VERSION ""

NS_ :

BS_:

BU_: XXX
BO_ 62 ENGINE_DATA: 48 XXX
 SG_ ENGINE_DATA_CHECKSUM_0 : 0|8@1+ (1,0) [0|255] "" XXX
 SG_ ENGINE_DATA_COUNTER_0 : 8|4@1+ (1,0) [0|15] "" XXX
 SG_ NEW_SIGNAL_4 : 17|10@0+ (1,0) [0|255] "" XXX
 SG_ NEW_SIGNAL_5 : 18|1@0+ (1,0) [0|1] "" XXX
 SG_ NEW_SIGNAL_1 : 23|1@0+ (1,0) [0|1] "" XXX
 SG_ ACCEL : 38|15@0- (1,0) [0|255] "" XXX
 SG_ NEW_SIGNAL_8 : 39|1@0+ (1,0) [0|1] "" XXX
 SG_ NEW_SIGNAL_2 : 55|1@0+ (1,0) [0|1] "" XXX
 SG_ ENGINE_DATA_CHECKSUM_1 : 64|8@1+ (1,0) [0|255] "" XXX
 SG_ ENGINE_DATA_COUNTER_1 : 72|4@1+ (1,0) [0|15] "" XXX
 SG_ GAS_POS : 85|14@0+ (1,-600) [0|127] "" XXX
 SG_ SPEED : 103|16@0+ (0.014184,-425.52) [-425.52|504] "kmh" XXX
 SG_ NEW_SIGNAL_6 : 119|16@0+ (1,-32768) [-32768|32767] "" XXX
 SG_ ENGINE_DATA_CHECKSUM_2 : 128|8@1+ (1,0) [0|255] "" XXX
 SG_ ENGINE_DATA_COUNTER_2 : 136|4@1+ (1,0) [0|15] "" XXX
 SG_ NEW_SIGNAL_15 : 151|16@0+ (1,-32768) [-32768|32767] "" XXX
 SG_ NEW_SIGNAL_11 : 166|7@0+ (1,0) [0|127] "" XXX
 SG_ NEW_SIGNAL_12 : 174|7@0+ (1,0) [0|127] "" XXX
 SG_ GAS : 183|8@0+ (1,0) [0|255] "" XXX
 SG_ GAS_PEDAL : 191|8@0+ (1,0) [0|255] "" XXX
 SG_ ENGINE_DATA_CHECKSUM_3 : 192|8@1+ (1,0) [0|255] "" XXX
 SG_ ENGINE_DATA_COUNTER_3 : 200|4@1+ (1,0) [0|15] "" XXX
 SG_ GEAR : 208|3@1+ (1,0) [0|63] "" XXX
 SG_ GEAR_BUTTON : 211|3@1+ (1,0) [0|7] "" XXX
 SG_ CC_STATE : 218|2@0+ (1,0) [0|7] "" XXX
 SG_ BRAKE_PRESS : 220|1@0+ (1,0) [0|1] "" XXX
 SG_ CRUIZE_SPEED : 229|7@0+ (1,0) [0|63] "" XXX
 SG_ SWITCH_TO_P : 234|1@0+ (1,0) [0|1] "" XXX
 SG_ NEW_SIGNAL_3 : 245|1@0+ (1,0) [0|1] "" XXX
 SG_ ENGINE_DATA_CHECKSUM_4 : 256|8@1+ (1,0) [0|255] "" XXX
 SG_ ENGINE_DATA_COUNTER_4 : 264|4@1+ (1,0) [0|15] "" XXX
 SG_ NEW_SIGNAL_14 : 279|16@0+ (1,-32768) [-32768|32767] "" XXX

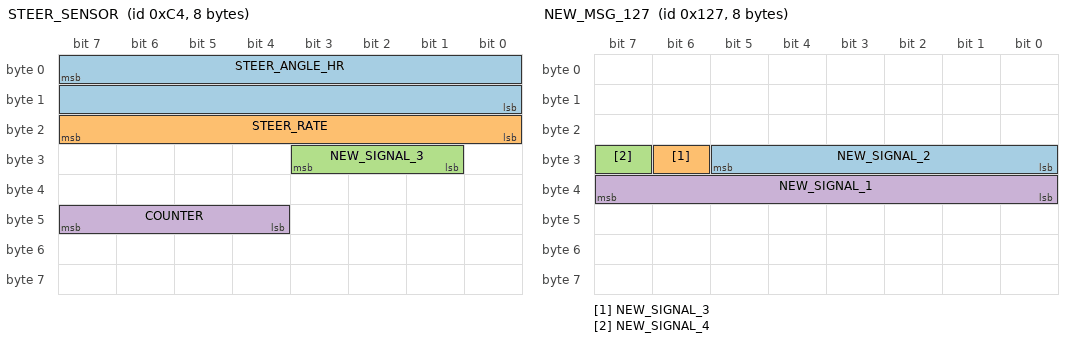
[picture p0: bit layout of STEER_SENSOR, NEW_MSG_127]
BO_ 196 STEER_SENSOR: 8 XXX
 SG_ STEER_ANGLE_HR : 7|16@0+ (0.0625,-2048) [-2048|2047.9375] "deg" XXX
 SG_ STEER_RATE : 16|8@1+ (4,0) [0|1020] "deg/s" XXX
 SG_ NEW_SIGNAL_3 : 25|3@1+ (1,0) [0|3] "" XXX
 SG_ COUNTER : 44|4@1+ (1,0) [0|15] "" XXX

BO_ 295 NEW_MSG_127: 8 XXX
 SG_ NEW_SIGNAL_2 : 24|6@1+ (1,0) [0|63] "" XXX
 SG_ NEW_SIGNAL_3 : 30|1@0+ (1,0) [0|1] "" XXX
 SG_ NEW_SIGNAL_4 : 31|1@0+ (1,0) [0|1] "" XXX
 SG_ NEW_SIGNAL_1 : 39|8@0- (1,0) [0|65535] "" XXX

BO_ 296 NEW_MSG_128: 8 XXX
 SG_ NEW_SIGNAL_1 : 19|12@0+ (1,0) [0|4095] "" XXX

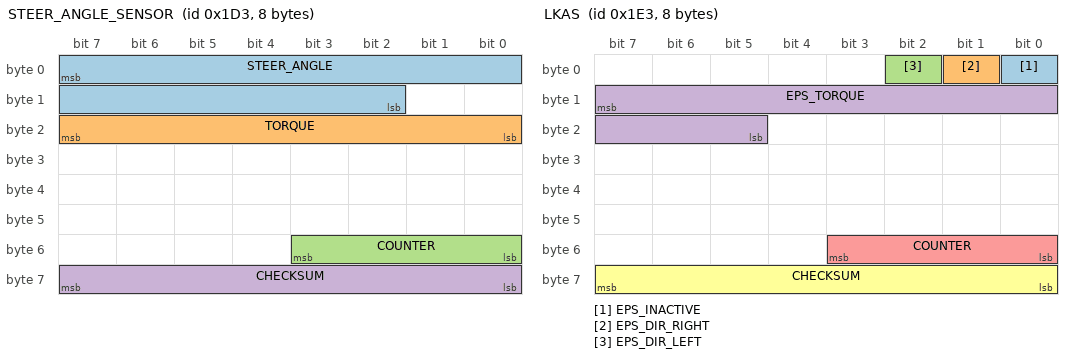
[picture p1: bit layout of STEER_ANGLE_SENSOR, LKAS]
BO_ 467 STEER_ANGLE_SENSOR: 8 XXX
 SG_ STEER_ANGLE : 7|14@0+ (0.1,-780) [-780|858.3] "" XXX
 SG_ TORQUE : 16|8@1- (1,0) [-128|127] "" XXX
 SG_ COUNTER : 48|4@1+ (1,0) [0|15] "" XXX
 SG_ CHECKSUM : 56|8@1+ (1,0) [0|255] "" XXX

BO_ 483 LKAS: 8 XXX
 SG_ EPS_INACTIVE : 0|1@1+ (1,0) [0|1] "" XXX
 SG_ EPS_DIR_RIGHT : 1|1@1+ (1,0) [0|1] "" XXX
 SG_ EPS_DIR_LEFT : 2|1@1+ (1,0) [0|1] "" XXX
 SG_ EPS_TORQUE : 15|11@0+ (1,-1024) [-1024|1023] "" XXX
 SG_ COUNTER : 48|4@1+ (1,0) [0|15] "" XXX
 SG_ CHECKSUM : 63|8@0+ (1,0) [0|255] "" XXX

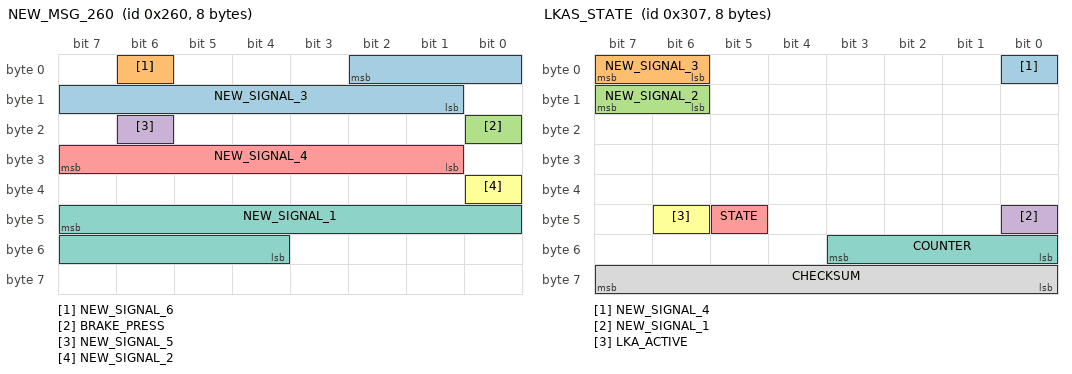
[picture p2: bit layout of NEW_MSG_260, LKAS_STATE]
BO_ 608 NEW_MSG_260: 8 XXX
 SG_ NEW_SIGNAL_3 : 2|10@0+ (1,0) [0|1023] "" XXX
 SG_ NEW_SIGNAL_6 : 6|1@0+ (1,0) [0|1] "" XXX
 SG_ BRAKE_PRESS : 16|1@0+ (1,0) [0|1] "" XXX
 SG_ NEW_SIGNAL_5 : 22|1@0+ (1,0) [0|1] "" XXX
 SG_ NEW_SIGNAL_4 : 31|7@0+ (1,0) [0|127] "" XXX
 SG_ NEW_SIGNAL_2 : 32|1@0+ (1,0) [0|65535] "" XXX
 SG_ NEW_SIGNAL_1 : 47|12@0- (1,0) [0|4095] "" XXX

BO_ 647 NEW_MSG_287: 8 XXX
 SG_ EPB_STATUS : 5|2@1+ (1,0) [0|3] "" XXX
 SG_ SEATBELT_LOCK : 25|1@0+ (1,0) [0|1] "" XXX

BO_ 666 BRAKE_DATA: 8 XXX
 SG_ NEW_SIGNAL_1 : 3|6@0+ (1,0) [0|63] "" XXX
 SG_ BRAKE_POS : 21|12@0- (1,-100) [0|511] "" XXX

BO_ 745 NEW_MSG_2E9: 8 XXX

BO_ 746 DOOR: 8 XXX
 SG_ NEW_SIGNAL_2 : 0|3@1+ (1,0) [0|7] "" XXX
 SG_ NEW_SIGNAL_1 : 11|3@1+ (1,0) [0|7] "" XXX

BO_ 773 NEW_MSG_305: 8 XXX
 SG_ NEW_SIGNAL_2 : 48|4@1+ (1,0) [0|15] "" XXX
 SG_ NEW_SIGNAL_1 : 63|8@0+ (1,0) [0|255] "" XXX

BO_ 775 LKAS_STATE: 8 XXX
 SG_ NEW_SIGNAL_4 : 0|1@0+ (1,0) [0|1] "" XXX
 SG_ NEW_SIGNAL_3 : 6|2@1+ (1,0) [0|3] "" XXX
 SG_ NEW_SIGNAL_2 : 14|2@1+ (1,0) [0|3] "" XXX
 SG_ NEW_SIGNAL_1 : 40|1@0+ (1,0) [0|1] "" XXX
 SG_ STATE : 45|1@0+ (1,0) [0|1] "" XXX
 SG_ LKA_ACTIVE : 46|1@1+ (1,0) [0|3] "" XXX
 SG_ COUNTER : 48|4@1+ (1,0) [0|15] "" XXX
 SG_ CHECKSUM : 63|8@0+ (1,0) [0|255] "" XXX

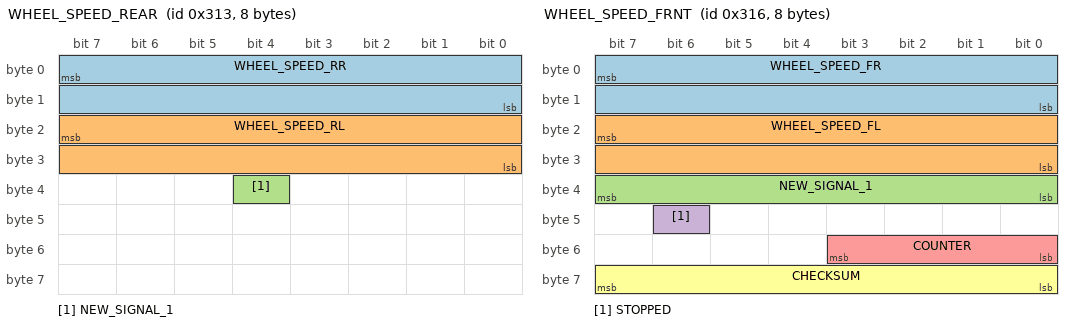
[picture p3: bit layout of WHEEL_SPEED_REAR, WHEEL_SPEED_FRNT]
BO_ 787 WHEEL_SPEED_REAR: 8 XXX
 SG_ WHEEL_SPEED_RR : 7|16@0+ (0.00828,0) [0|32767] "" XXX
 SG_ WHEEL_SPEED_RL : 23|16@0+ (0.00828,0) [0|32767] "" XXX
 SG_ NEW_SIGNAL_1 : 36|1@0+ (1,0) [0|1] "" XXX

BO_ 790 WHEEL_SPEED_FRNT: 8 XXX
 SG_ WHEEL_SPEED_FR : 7|16@0- (0.00829,0) [-2000|32767] "kmh" XXX
 SG_ WHEEL_SPEED_FL : 23|16@0- (0.00829,0) [0|32767] "" XXX
 SG_ NEW_SIGNAL_1 : 32|8@1+ (1,0) [0|31] "" XXX
 SG_ STOPPED : 46|1@0+ (1,0) [0|1] "" XXX
 SG_ COUNTER : 48|4@1+ (1,0) [0|15] "" XXX
 SG_ CHECKSUM : 56|8@1+ (1,0) [0|255] "" XXX

BO_ 793 NEW_MSG_319: 8 XXX

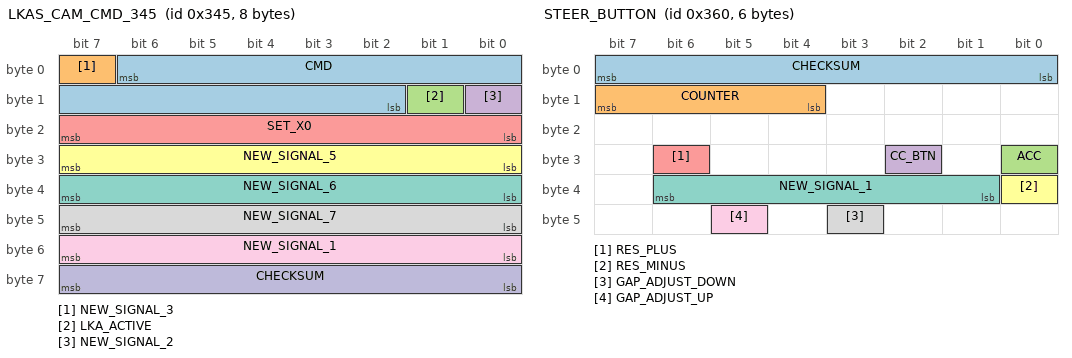
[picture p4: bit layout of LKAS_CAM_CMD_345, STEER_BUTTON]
BO_ 837 LKAS_CAM_CMD_345: 8 XXX
 SG_ CMD : 6|13@0- (1,0) [-4096|4095] "" XXX
 SG_ NEW_SIGNAL_3 : 7|1@0+ (1,0) [0|1] "" XXX
 SG_ LKA_ACTIVE : 9|1@0+ (1,0) [0|1] "" XXX
 SG_ NEW_SIGNAL_2 : 8|1@0+ (1,0) [0|1] "" XXX
 SG_ SET_X0 : 16|8@1+ (1,0) [0|255] "" XXX
 SG_ NEW_SIGNAL_5 : 31|8@0- (1,0) [0|255] "" XXX
 SG_ NEW_SIGNAL_6 : 39|8@0+ (1,0) [0|255] "" XXX
 SG_ NEW_SIGNAL_7 : 47|8@0+ (1,0) [0|255] "" XXX
 SG_ NEW_SIGNAL_1 : 55|8@0+ (1,0) [0|255] "" XXX
 SG_ CHECKSUM : 56|8@1+ (1,0) [0|255] "" XXX

BO_ 864 STEER_BUTTON: 6 XXX
 SG_ CHECKSUM : 0|8@1+ (1,0) [0|255] "" XXX
 SG_ COUNTER : 12|4@1+ (1,0) [0|15] "" XXX
 SG_ ACC : 24|1@0+ (1,0) [0|1] "" XXX
 SG_ CC_BTN : 26|1@0+ (1,0) [0|1] "" XXX
 SG_ RES_PLUS : 30|1@0+ (1,0) [0|1] "" XXX
 SG_ RES_MINUS : 32|1@0+ (1,0) [0|1] "" XXX
 SG_ NEW_SIGNAL_1 : 38|6@0+ (1,0) [0|1] "" XXX
 SG_ GAP_ADJUST_DOWN : 43|1@0+ (1,0) [0|1] "" XXX
 SG_ GAP_ADJUST_UP : 45|1@0+ (1,0) [0|1] "" XXX

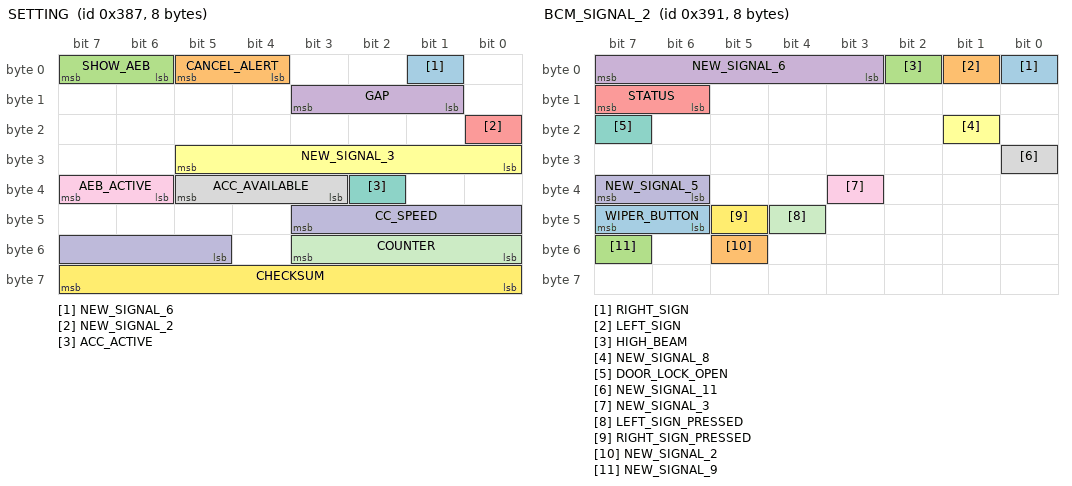
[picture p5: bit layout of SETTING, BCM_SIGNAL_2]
BO_ 903 SETTING: 8 XXX
 SG_ NEW_SIGNAL_6 : 1|1@0+ (1,0) [0|1] "" XXX
 SG_ CANCEL_ALERT : 5|2@0+ (1,0) [0|1] "" XXX
 SG_ SHOW_AEB : 6|2@1+ (1,0) [0|3] "" XXX
 SG_ GAP : 11|3@0+ (1,0) [0|7] "" XXX
 SG_ NEW_SIGNAL_2 : 16|1@0+ (1,0) [0|1] "" XXX
 SG_ NEW_SIGNAL_3 : 29|6@0+ (1,0) [0|31] "" XXX
 SG_ ACC_ACTIVE : 34|1@0+ (1,0) [0|1] "" XXX
 SG_ ACC_AVAILABLE : 35|3@1+ (1,0) [0|15] "" XXX
 SG_ AEB_ACTIVE : 38|2@1+ (1,0) [0|3] "" XXX
 SG_ CC_SPEED : 43|7@0+ (1,0) [0|1023] "" XXX
 SG_ COUNTER : 51|4@0+ (1,0) [0|15] "" XXX
 SG_ CHECKSUM : 63|8@0+ (1,0) [0|255] "" XXX

BO_ 913 BCM_SIGNAL_2: 8 XXX
 SG_ RIGHT_SIGN : 0|1@0+ (1,0) [0|1] "" XXX
 SG_ LEFT_SIGN : 1|1@0+ (1,0) [0|1] "" XXX
 SG_ HIGH_BEAM : 2|1@0+ (1,0) [0|1] "" XXX
 SG_ NEW_SIGNAL_6 : 3|5@1+ (1,0) [0|31] "" XXX
 SG_ STATUS : 15|2@0+ (1,0) [0|63] "" XXX
 SG_ NEW_SIGNAL_8 : 17|1@0+ (1,0) [0|1] "" XXX
 SG_ DOOR_LOCK_OPEN : 23|1@0+ (1,0) [0|1] "" XXX
 SG_ NEW_SIGNAL_11 : 24|1@0+ (1,0) [0|1] "" XXX
 SG_ NEW_SIGNAL_3 : 35|1@0+ (1,0) [0|1] "" XXX
 SG_ NEW_SIGNAL_5 : 38|2@1+ (1,0) [0|3] "" XXX
 SG_ LEFT_SIGN_PRESSED : 44|1@0+ (1,0) [0|1] "" XXX
 SG_ RIGHT_SIGN_PRESSED : 45|1@0+ (1,0) [0|1] "" XXX
 SG_ WIPER_BUTTON : 46|2@1+ (1,0) [0|3] "" XXX
 SG_ NEW_SIGNAL_2 : 53|1@0+ (1,0) [0|1] "" XXX
 SG_ NEW_SIGNAL_9 : 55|1@0+ (1,0) [0|1] "" XXX

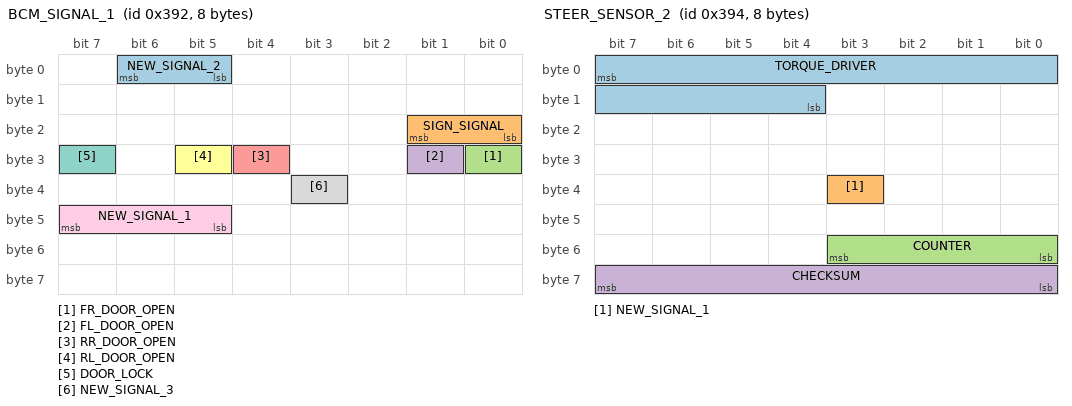
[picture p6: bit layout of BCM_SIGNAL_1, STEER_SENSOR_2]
BO_ 914 BCM_SIGNAL_1: 8 XXX
 SG_ NEW_SIGNAL_2 : 5|2@1+ (1,0) [0|3] "" XXX
 SG_ SIGN_SIGNAL : 16|2@1+ (1,0) [0|3] "" XXX
 SG_ FR_DOOR_OPEN : 24|1@0+ (1,0) [0|1] "" XXX
 SG_ FL_DOOR_OPEN : 25|1@0+ (1,0) [0|1] "" XXX
 SG_ RR_DOOR_OPEN : 28|1@0+ (1,0) [0|1] "" XXX
 SG_ RL_DOOR_OPEN : 29|1@0+ (1,0) [0|1] "" XXX
 SG_ DOOR_LOCK : 31|1@0+ (1,0) [0|1] "" XXX
 SG_ NEW_SIGNAL_3 : 35|1@0+ (1,0) [0|1] "" XXX
 SG_ NEW_SIGNAL_1 : 47|3@0+ (1,0) [0|7] "" XXX

BO_ 916 STEER_SENSOR_2: 8 XXX
 SG_ TORQUE_DRIVER : 7|12@0- (0.24,0) [-491.52|491.28] "" XXX
 SG_ NEW_SIGNAL_1 : 35|1@0+ (1,0) [0|1] "" XXX
 SG_ COUNTER : 48|4@1+ (1,0) [0|15] "" XXX
 SG_ CHECKSUM : 56|8@1+ (1,0) [0|255] "" XXX

BO_ 930 ACC_CMD: 8 XXX
 SG_ CMD : 6|10@0- (1,0) [-511|511] "" XXX
 SG_ ACCEL_ON : 7|1@0+ (1,0) [0|1] "" XXX
 SG_ ACC_STATE : 9|2@0+ (1,0) [0|3] "" XXX
 SG_ STOPPED : 10|1@0+ (1,0) [0|1] "" XXX
 SG_ ACC_STATE_2 : 11|2@1+ (1,0) [0|15] "" XXX
 SG_ NEW_SIGNAL_12 : 16|1@0+ (1,0) [0|1] "" XXX
 SG_ NEW_SIGNAL_9 : 17|1@0+ (1,0) [0|1] "" XXX
 SG_ NEW_SIGNAL_2 : 22|5@0+ (1,0) [0|31] "" XXX
 SG_ STOPPING : 23|1@0+ (1,0) [0|1] "" XXX
 SG_ NEW_SIGNAL_13 : 24|1@0+ (1,0) [0|1] "" XXX
 SG_ NEW_SIGNAL_8 : 25|1@0+ (1,0) [0|1] "" XXX
 SG_ NEW_SIGNAL_5 : 30|5@0+ (1,0) [0|31] "" XXX
 SG_ NEW_SIGNAL_6 : 31|1@0+ (1,0) [0|1] "" XXX
 SG_ NEW_SIGNAL_10 : 32|7@1+ (1,0) [0|255] "" XXX
 SG_ NEW_SIGNAL_3 : 39|1@0+ (1,0) [0|1] "" XXX
 SG_ NEW_SIGNAL_4 : 40|7@1- (1,0) [0|255] "" XXX
 SG_ GAS_PRESSED : 47|1@0+ (1,0) [0|1] "" XXX
 SG_ COUNTER : 48|4@1+ (1,0) [0|15] "" XXX
 SG_ AEB_REQ_STOP : 55|4@0+ (1,0) [0|15] "" XXX
 SG_ CHECKSUM : 56|8@1+ (1,0) [0|255] "" XXX

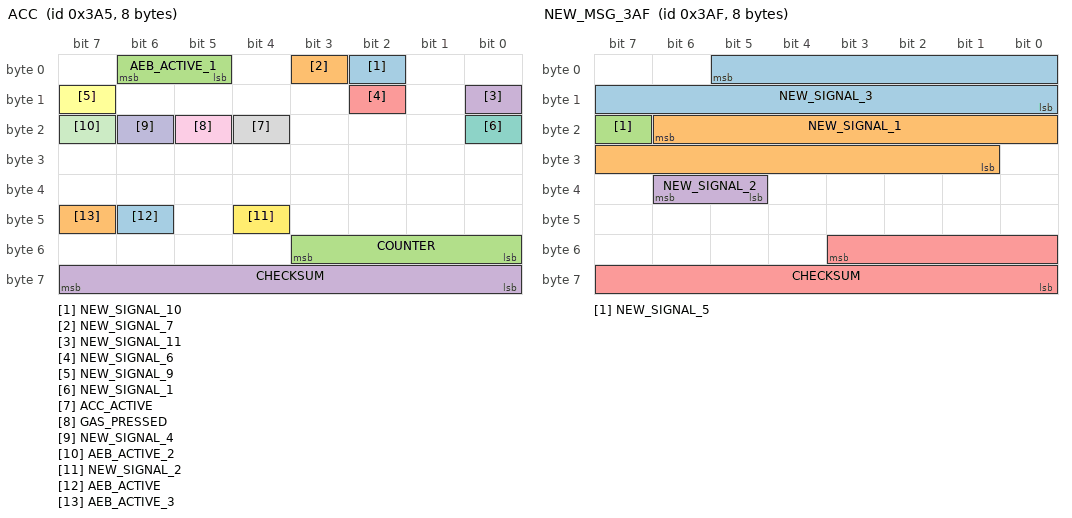
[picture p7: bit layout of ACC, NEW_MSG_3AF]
BO_ 933 ACC: 8 XXX
 SG_ NEW_SIGNAL_10 : 2|1@0+ (1,0) [0|1] "" XXX
 SG_ NEW_SIGNAL_7 : 3|1@0+ (1,0) [0|1] "" XXX
 SG_ AEB_ACTIVE_1 : 5|2@1+ (1,0) [0|3] "" XXX
 SG_ NEW_SIGNAL_11 : 8|1@0+ (1,0) [0|1] "" XXX
 SG_ NEW_SIGNAL_6 : 10|1@0+ (1,0) [0|1] "" XXX
 SG_ NEW_SIGNAL_9 : 15|1@0+ (1,0) [0|1] "" XXX
 SG_ NEW_SIGNAL_1 : 16|1@0+ (1,0) [0|1] "" XXX
 SG_ ACC_ACTIVE : 20|1@0+ (1,0) [0|1] "" XXX
 SG_ GAS_PRESSED : 21|1@0+ (1,0) [0|1] "" XXX
 SG_ NEW_SIGNAL_4 : 22|1@0+ (1,0) [0|1] "" XXX
 SG_ AEB_ACTIVE_2 : 23|1@0+ (1,0) [0|1] "" XXX
 SG_ NEW_SIGNAL_2 : 44|1@0+ (1,0) [0|1] "" XXX
 SG_ AEB_ACTIVE : 46|1@0+ (1,0) [0|1] "" XXX
 SG_ AEB_ACTIVE_3 : 47|1@0+ (1,0) [0|1] "" XXX
 SG_ COUNTER : 48|4@1+ (1,0) [0|15] "" XXX
 SG_ CHECKSUM : 56|8@1+ (1,0) [0|255] "" XXX

BO_ 935 NEW_MSG_3A7: 24 XXX

BO_ 943 NEW_MSG_3AF: 8 XXX
 SG_ NEW_SIGNAL_3 : 5|14@0+ (1,0) [0|16383] "" XXX
 SG_ NEW_SIGNAL_1 : 22|14@0+ (1,0) [0|16383] "" XXX
 SG_ NEW_SIGNAL_5 : 23|1@0+ (1,0) [0|1] "" XXX
 SG_ NEW_SIGNAL_2 : 37|2@1+ (1,0) [0|3] "" XXX
 SG_ CHECKSUM : 51|12@0+ (1,0) [0|4095] "" XXX

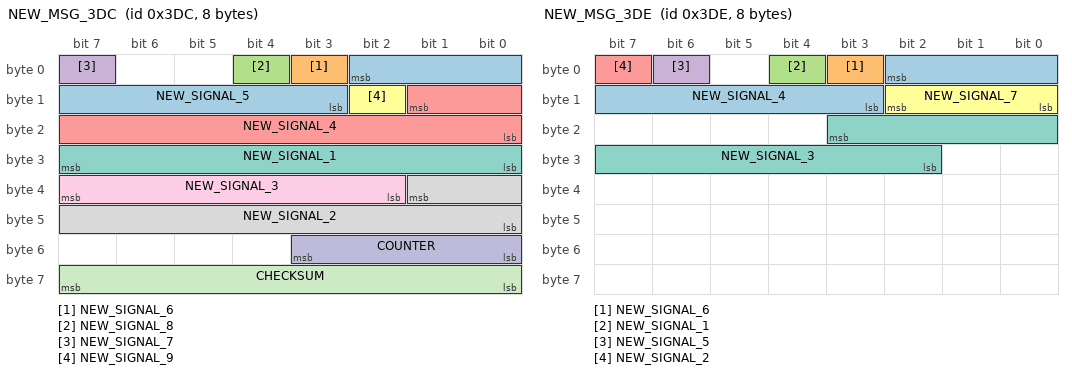
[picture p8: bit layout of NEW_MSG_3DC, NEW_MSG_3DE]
BO_ 988 NEW_MSG_3DC: 8 XXX
 SG_ NEW_SIGNAL_5 : 2|8@0+ (1,0) [0|255] "" XXX
 SG_ NEW_SIGNAL_6 : 3|1@0+ (1,0) [0|1] "" XXX
 SG_ NEW_SIGNAL_8 : 4|1@0+ (1,0) [0|1] "" XXX
 SG_ NEW_SIGNAL_7 : 7|1@1+ (1,0) [0|15] "" XXX
 SG_ NEW_SIGNAL_4 : 9|10@0+ (1,0) [0|8191] "" XXX
 SG_ NEW_SIGNAL_9 : 10|1@0+ (1,0) [0|1] "" XXX
 SG_ NEW_SIGNAL_1 : 31|8@0+ (1,0) [0|8191] "" XXX
 SG_ NEW_SIGNAL_2 : 33|10@0+ (1,0) [0|65535] "" XXX
 SG_ NEW_SIGNAL_3 : 34|6@1+ (1,0) [0|63] "" XXX
 SG_ COUNTER : 48|4@1+ (1,0) [0|15] "" XXX
 SG_ CHECKSUM : 56|8@1+ (1,0) [0|255] "" XXX

BO_ 990 NEW_MSG_3DE: 8 XXX
 SG_ NEW_SIGNAL_4 : 2|8@0+ (1,0) [0|255] "" XXX
 SG_ NEW_SIGNAL_6 : 3|1@0+ (1,0) [0|1] "" XXX
 SG_ NEW_SIGNAL_1 : 4|1@0+ (1,0) [0|1] "" XXX
 SG_ NEW_SIGNAL_5 : 6|1@0+ (1,0) [0|1] "" XXX
 SG_ NEW_SIGNAL_2 : 7|1@0+ (1,0) [0|1] "" XXX
 SG_ NEW_SIGNAL_7 : 10|3@0+ (1,0) [0|7] "" XXX
 SG_ NEW_SIGNAL_3 : 19|10@0+ (1,0) [0|255] "" XXX

BO_ 994 NEW_MSG_3E2: 8 XXX
 SG_ NEW_SIGNAL_2 : 7|1@0+ (1,0) [0|1] "" XXX
 SG_ NEW_SIGNAL_1 : 21|10@0- (1,0) [0|1023] "" XXX

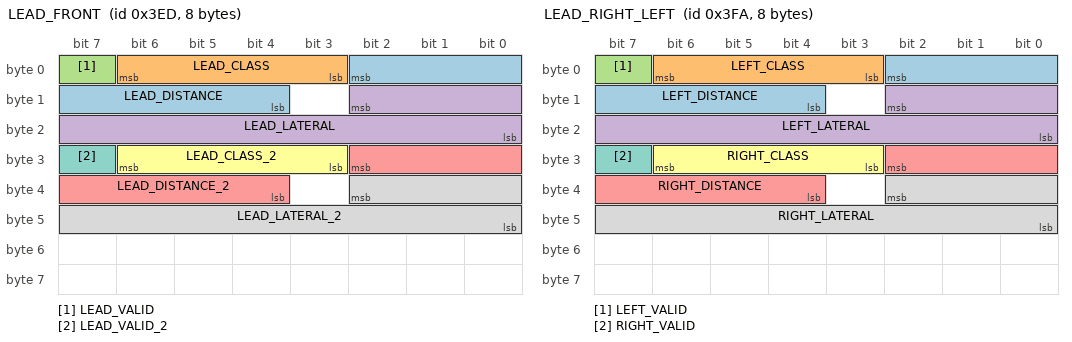
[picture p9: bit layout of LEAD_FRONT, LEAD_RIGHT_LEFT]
BO_ 1005 LEAD_FRONT: 8 XXX
 SG_ LEAD_DISTANCE : 2|7@0+ (1,0) [0|127] "m" XXX
 SG_ LEAD_CLASS : 6|4@0+ (1,0) [0|15] "" XXX
 SG_ LEAD_VALID : 7|1@0+ (1,0) [0|1] "" XXX
 SG_ LEAD_LATERAL : 10|11@0+ (0.04,-40) [-40|41.88] "m" XXX
 SG_ LEAD_DISTANCE_2 : 26|7@0+ (1,0) [0|127] "m" XXX
 SG_ LEAD_CLASS_2 : 30|4@0+ (1,0) [0|15] "" XXX
 SG_ LEAD_VALID_2 : 31|1@0+ (1,0) [0|1] "" XXX
 SG_ LEAD_LATERAL_2 : 34|11@0+ (0.04,-40) [-40|41.88] "m" XXX

BO_ 1008 NEW_MSG_3F0: 8 XXX

BO_ 1018 LEAD_RIGHT_LEFT: 8 XXX
 SG_ LEFT_DISTANCE : 2|7@0+ (1,0) [0|127] "m" XXX
 SG_ LEFT_CLASS : 6|4@0+ (1,0) [0|15] "" XXX
 SG_ LEFT_VALID : 7|1@0+ (1,0) [0|1] "" XXX
 SG_ LEFT_LATERAL : 10|11@0+ (0.04,-40) [-40|41.88] "m" XXX
 SG_ RIGHT_DISTANCE : 26|7@0+ (1,0) [0|127] "m" XXX
 SG_ RIGHT_CLASS : 30|4@0+ (1,0) [0|15] "" XXX
 SG_ RIGHT_VALID : 31|1@0+ (1,0) [0|1] "" XXX
 SG_ RIGHT_LATERAL : 34|11@0+ (0.04,-40) [-40|41.88] "m" XXX

BO_ 1020 HUD_ALERT: 8 XXX
 SG_ NEW_SIGNAL_1 : 0|8@1+ (1,0) [0|255] "" XXX
 SG_ NEW_SIGNAL_2 : 8|8@1+ (1,0) [0|255] "" XXX
 SG_ NEW_SIGNAL_6 : 16|2@1+ (1,0) [0|3] "" XXX
 SG_ NEW_SIGNAL_5 : 18|1@1+ (1,0) [0|1] "" XXX
 SG_ NEW_SIGNAL_7 : 19|2@1+ (1,0) [0|3] "" XXX
 SG_ NEW_SIGNAL_8 : 21|3@1+ (1,0) [0|7] "" XXX
 SG_ NEW_SIGNAL_9 : 24|1@1+ (1,0) [0|1] "" XXX
 SG_ ICA_WARNING : 25|3@1+ (1,0) [0|7] "" XXX
 SG_ NEW_SIGNAL_10 : 28|1@1+ (1,0) [0|1] "" XXX
 SG_ NEW_SIGNAL_4 : 29|2@1+ (1,0) [0|3] "" XXX
 SG_ NEW_SIGNAL_11 : 31|1@1+ (1,0) [0|1] "" XXX
 SG_ NEW_SIGNAL_12 : 32|2@1+ (1,0) [0|3] "" XXX
 SG_ NEW_SIGNAL_13 : 34|1@1+ (1,0) [0|1] "" XXX
 SG_ NEW_SIGNAL_14 : 35|2@1+ (1,0) [0|3] "" XXX
 SG_ NEW_SIGNAL_15 : 37|1@1+ (1,0) [0|1] "" XXX
 SG_ STEER_WARNING : 38|1@0+ (1,0) [0|1] "" XXX
 SG_ NEW_SIGNAL_16 : 39|1@1+ (1,0) [0|1] "" XXX
 SG_ NEW_SIGNAL_3 : 44|9@0+ (1,-256) [-256|255] "" XXX
 SG_ NEW_SIGNAL_17 : 45|3@1+ (1,0) [0|7] "" XXX
 SG_ COUNTER : 48|4@1+ (1,0) [0|15] "" XXX
 SG_ CHECKSUM : 63|8@0+ (1,0) [0|255] "" XXX

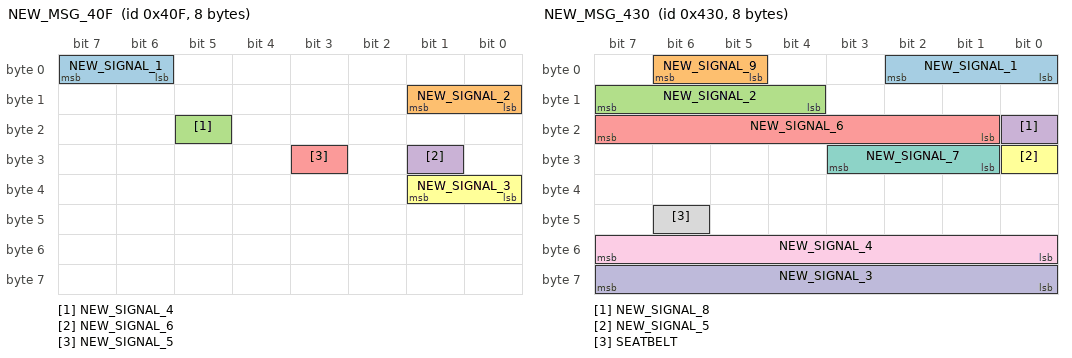
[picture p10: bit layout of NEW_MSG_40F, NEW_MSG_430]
BO_ 1039 NEW_MSG_40F: 8 XXX
 SG_ NEW_SIGNAL_1 : 6|2@1+ (1,0) [0|3] "" XXX
 SG_ NEW_SIGNAL_2 : 8|2@1+ (1,0) [0|3] "" XXX
 SG_ NEW_SIGNAL_4 : 21|1@0+ (1,0) [0|1] "" XXX
 SG_ NEW_SIGNAL_6 : 25|1@0+ (1,0) [0|1] "" XXX
 SG_ NEW_SIGNAL_5 : 27|1@0+ (1,0) [0|1] "" XXX
 SG_ NEW_SIGNAL_3 : 32|2@1+ (1,0) [0|3] "" XXX

BO_ 1063 NEW_MSG_427: 8 XXX
 SG_ NEW_SIGNAL_1 : 4|5@0+ (1,0) [0|31] "" XXX
 SG_ NEW_SIGNAL_2 : 14|2@1+ (1,0) [0|3] "" XXX

BO_ 1072 NEW_MSG_430: 8 XXX
 SG_ NEW_SIGNAL_1 : 0|3@1+ (1,0) [0|3] "" XXX
 SG_ NEW_SIGNAL_9 : 5|2@1+ (1,0) [0|3] "" XXX
 SG_ NEW_SIGNAL_2 : 12|4@1+ (1,0) [0|15] "" XXX
 SG_ NEW_SIGNAL_8 : 16|1@0+ (1,0) [0|1] "" XXX
 SG_ NEW_SIGNAL_6 : 17|7@1+ (1,0) [0|127] "" XXX
 SG_ NEW_SIGNAL_5 : 24|1@0+ (1,0) [0|1] "" XXX
 SG_ NEW_SIGNAL_7 : 27|3@0+ (1,0) [0|7] "" XXX
 SG_ SEATBELT : 46|1@0+ (1,0) [0|1] "" XXX
 SG_ NEW_SIGNAL_4 : 48|8@1+ (1,0) [0|255] "" XXX
 SG_ NEW_SIGNAL_3 : 56|8@1+ (1,0) [0|255] "" XXX

BO_ 1077 NEW_MSG_435: 8 XXX
 SG_ NEW_SIGNAL_1 : 23|8@0+ (1,0) [0|255] "" XXX

BO_ 1114 NEW_MSG_45A: 8 XXX
 SG_ AVM_PRESSED : 50|1@0+ (1,0) [0|1] "" XXX

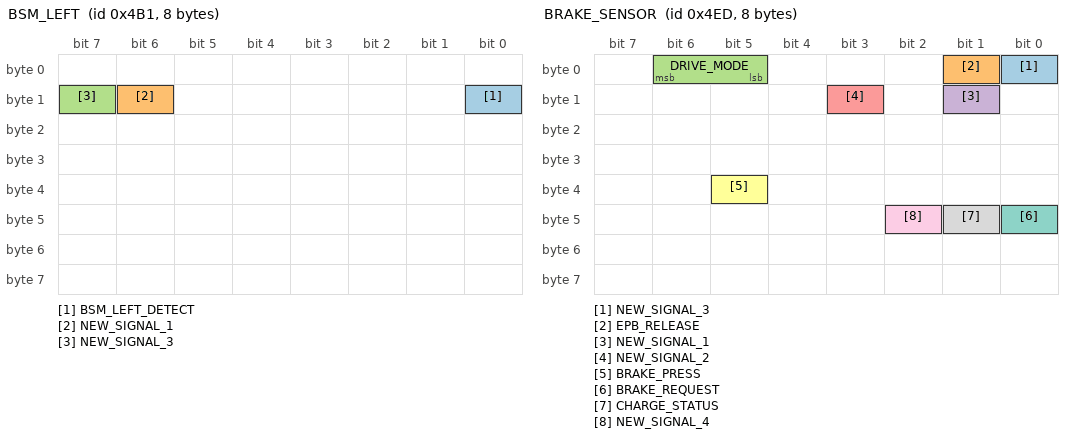
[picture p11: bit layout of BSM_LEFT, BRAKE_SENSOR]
BO_ 1201 BSM_LEFT: 8 XXX
 SG_ BSM_LEFT_DETECT : 8|1@0+ (1,0) [0|1] "" XXX
 SG_ NEW_SIGNAL_1 : 14|1@0+ (1,0) [0|1] "" XXX
 SG_ NEW_SIGNAL_3 : 15|1@0+ (1,0) [0|1] "" XXX

BO_ 1203 BSM_RIGHT: 8 XXX
 SG_ BSM_RIGHT_DETECT : 4|1@0+ (1,0) [0|1] "" XXX
 SG_ NEW_SIGNAL_1 : 14|1@0+ (1,0) [0|1] "" XXX

BO_ 1245 NEW_MSG_4DD: 8 XXX
 SG_ NEW_SIGNAL_2 : 48|4@1+ (1,0) [0|15] "" XXX
 SG_ NEW_SIGNAL_1 : 63|8@0+ (1,0) [0|255] "" XXX

BO_ 1251 NEW_MSG_4E3: 8 XXX
 SG_ NEW_SIGNAL_1 : 5|1@0+ (1,0) [0|1] "" XXX
 SG_ NEW_SIGNAL_2 : 6|2@1+ (1,0) [0|3] "" XXX

BO_ 1261 BRAKE_SENSOR: 8 XXX
 SG_ NEW_SIGNAL_3 : 0|1@0+ (1,0) [0|1] "" XXX
 SG_ EPB_RELEASE : 1|1@0+ (1,0) [0|1] "" XXX
 SG_ DRIVE_MODE : 6|2@0+ (1,0) [0|3] "" XXX
 SG_ NEW_SIGNAL_1 : 9|1@0+ (1,0) [0|1] "" XXX
 SG_ NEW_SIGNAL_2 : 11|1@0+ (1,0) [0|1] "" XXX
 SG_ BRAKE_PRESS : 37|1@0+ (1,0) [0|1] "" XXX
 SG_ BRAKE_REQUEST : 40|1@0+ (1,0) [0|1] "" XXX
 SG_ CHARGE_STATUS : 41|1@0+ (1,0) [0|1] "" XXX
 SG_ NEW_SIGNAL_4 : 42|1@0+ (1,0) [0|1] "" XXX

BO_ 1266 carlinko: 8 XXX
 SG_ NEW_SIGNAL_1 : 6|2@1+ (1,0) [0|3] "" XXX
 SG_ NEW_SIGNAL_2 : 62|1@0+ (1,0) [0|1] "" XXX

BO_ 1270 EPB: 2 XXX
 SG_ EPB_SIGNAL : 5|2@1+ (1,0) [0|3] "" XXX
 SG_ EPB_ACTIVE : 13|1@0+ (1,0) [0|1] "" XXX

BO_ 1272 Window_Command: 8 XXX
 SG_ NEW_SIGNAL_1 : 61|4@0+ (1,0) [0|15] "" XXX

BO_ 1276 AEB_COMMAND: 8 XXX
 SG_ AEB_ACTIVE : 20|1@1+ (1,0) [0|3] "" XXX

BO_ 1307 NEW_MSG_51B: 8 XXX

BO_ 1309 NEW_MSG_51D: 8 XXX
 SG_ NEW_SIGNAL_2 : 30|1@0+ (1,0) [0|1] "" XXX
 SG_ HDC_ACTIVE : 31|1@1+ (1,0) [0|3] "" XXX

BO_ 1333 NEW_MSG_535: 8 XXX

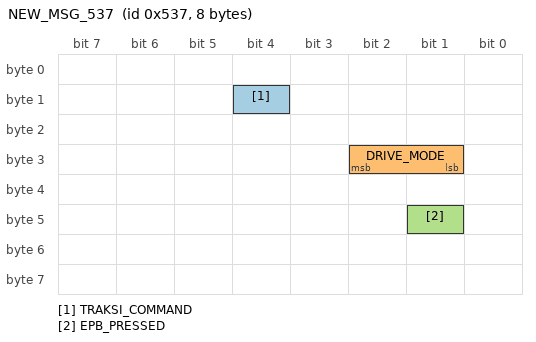
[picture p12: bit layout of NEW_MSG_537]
BO_ 1335 NEW_MSG_537: 8 XXX
 SG_ TRAKSI_COMMAND : 12|1@0+ (1,0) [0|1] "" XXX
 SG_ DRIVE_MODE : 25|2@1+ (1,0) [0|3] "" XXX
 SG_ EPB_PRESSED : 41|1@0+ (1,0) [0|1] "" XXX

CM_ BO_ 1020 "Every bit is defined so the openpilot relay repacks the camera frame byte for byte; undefined bits were dropped and the relayed CRC went stale.";
CM_ SG_ 1020 NEW_SIGNAL_4 "2 whenever the model sees both lane lines, ACC on or off; likely lane lines detected.";
CM_ SG_ 1020 NEW_SIGNAL_6 "1 or 2; 2 mostly with ACC active above ~60 kph. Meaning unconfirmed.";
CM_ SG_ 1020 NEW_SIGNAL_7 "1 or 2; 2 mostly with ACC active above ~60 kph. Reads 3 while the camera's own lane keeping steers (route 00000494 seg 15, 2 of 2 interventions) and 1 for ~2.7 s after one; likely the yellow HUD lane-line warning. Not confirmed on the cluster.";
CM_ SG_ 483 EPS_INACTIVE "1 only while lateral is off, and EPS_TORQUE then reads 1023 (raw 0x7FF). Bits 3-7 of byte 0 read a constant 10 (route 0000049e segs 30-31, 12k frames).";
CM_ SG_ 483 EPS_DIR_RIGHT "Set while EPS_TORQUE > ~+78, clear inside the deadband. Wheel turning right while set (mean rate -2.3 deg/s, route 00000494 seg 20).";
CM_ SG_ 483 EPS_DIR_LEFT "Set while EPS_TORQUE < ~-80, clear inside the deadband. Wheel turning left while set (mean rate +6.4 deg/s, route 00000494 seg 20).";
CM_ SG_ 483 EPS_TORQUE "Likely EPS motor output, sign opposite to openpilot (negative = left). corr -0.46 to the 0x345 angle command and to steering rate, -0.49 to angle error lagged 80 ms (route 0000049e segs 30-31); corr -0.63 to steering rate on route 00000494 seg 20. Unit unknown.";
CM_ SG_ 775 NEW_SIGNAL_2 "Reads 3 while the camera's own lane keeping steers, 1 otherwise: tracks LKAS_CAM_CMD_345.LKA_ACTIVE within 30 ms (corr 0.95, route 00000494 seg 15).";
CM_ SG_ 837 NEW_SIGNAL_2 "Undefined bit the camera sets on some frames (49 of 3000, route 00000494 seg 15); defined so the stock steering relay is byte exact.";
CM_ SG_ 1020 NEW_SIGNAL_3 "Centred on 0 (raw 256). With both lane lines seen: corr +0.52 to lane offset, -0.40 to curvature.";
CM_ SG_ 1020 NEW_SIGNAL_12 "3 on every frame of route 00000488.";
CM_ SG_ 1020 NEW_SIGNAL_14 "3 on every frame of route 00000488.";
CM_ BO_ 1005 "Front ADAS camera lead estimate (the car has no radar). Two 3-byte object slots; 07 FA EA marks an empty slot. No relative speed.";
CM_ SG_ 1005 LEAD_DISTANCE "Fit against the openpilot model lead on 21 stock-ACC segments: corr 0.96, model x = 0.95 * LEAD_DISTANCE + 2.7.";
CM_ SG_ 1005 LEAD_CLASS "Matched on video: 1 car, 2 truck, 3 motorcycle. 4 and 5 seen rarely, unidentified.";
CM_ SG_ 1005 LEAD_LATERAL "Positive left. Scale fit loosely (corr 0.73 against the model lead).";
CM_ BO_ 1018 "Adjacent-lane objects from the front camera, same slot layout as LEAD_FRONT. On 21 segments the first slot sat left in 98% of frames (median +2.6 m), the second right in 97% (median -3.1 m).";
CM_ SG_ 1005 LEAD_DISTANCE_2 "Same layout as the first slot; seen holding an 18 m car while a motorcycle took the first slot.";
CM_ BO_ 62 "Powertrain status. 48 bytes as six 8-byte blocks, each with its own checksum (byte 0) and 4-bit counter (low nibble of byte 1); bytes 40-47 are always zero.";
CM_ SG_ 62 SPEED "Signed speed, raw offset 30000: standstill mean 29999.0 (sd 7) over 16.8k stopped frames, negative through reverse (29847 at 2.1 kph backwards), route 000004ac segs 0-3. 70.5 counts per kph, fit against signed carState.vEgo R2 0.9991. Native unit is probably motor rpm through the ~9.2:1 reduction.";
CM_ SG_ 62 GAS "Throttle the powertrain is executing, not pedal travel. Ran up to 60 through a whole stock-ACC segment while the driver never touched the pedal (route 0000049e segs 20-23).";
CM_ SG_ 62 GAS_PEDAL "Driver accelerator pedal. Exactly 0 on all 5999 frames of that same ACC-driven segment, where the camera ACC_CMD.GAS_PRESSED also read 0 and GAS did not; rises with every gas press of a manual drive (route 000004ac segs 0-3). A driver override while ACC is engaged has not been captured yet, so the camera bit still owns gasPressed in that case.";
CM_ SG_ 62 ACCEL "Longitudinal acceleration. Against wheel-speed derived acceleration on a highway segment: 0.00157 m/s2 per count, R2 0.98, leading by 40 ms. Scale left at 1 because the fit drifts at low speed where road grade enters.";
CM_ SG_ 62 NEW_SIGNAL_6 "Offset binary about 32768. Zero at standstill and throughout reverse, negative while moving forward, updates at 5 Hz. Torque-like, unconfirmed.";
CM_ SG_ 62 NEW_SIGNAL_15 "Offset binary about 32768, never positive. Zero on 97% of town-driving frames but corr +0.96 to acceleration on a highway segment, and corr +1.00 to NEW_MSG_260.NEW_SIGNAL_1. Braking or regen torque, unit unknown.";
CM_ SG_ 62 NEW_SIGNAL_14 "Offset binary about 32768, small negatives (-61 to -1 on route 000004ac segs 0-3), constant on the highway segment.";
CM_ SG_ 62 GEAR "P=1, R=2, D=4 all observed on route 000004ac segs 0-3; N never selected.";
CM_ SG_ 62 CC_STATE "Always 0, including a full segment with the stock ACC engaged (route 0000049e segs 20-23). Cruise state comes from the camera ACC/ACC_CMD frames; the name is historical.";
CM_ SG_ 62 CRUIZE_SPEED "Always 0, including with the stock ACC engaged. Set speed comes from SETTING.CC_SPEED.";
VAL_ 62 GEAR 1 "P" 2 "R" 3 "N" 4 "D";
VAL_ 1005 LEAD_CLASS 1 "CAR" 2 "TRUCK" 3 "MOTORCYCLE";
VAL_ 1005 LEAD_CLASS_2 1 "CAR" 2 "TRUCK" 3 "MOTORCYCLE";
VAL_ 1018 LEFT_CLASS 1 "CAR" 2 "TRUCK" 3 "MOTORCYCLE";
VAL_ 1018 RIGHT_CLASS 1 "CAR" 2 "TRUCK" 3 "MOTORCYCLE";
VAL_ 62 GEAR_BUTTON 1 "Park Pressed" 3 "Netral Pressed" 4 "Drive Pressed" 2 "Reverse Pressed";
VAL_ 62 CC_STATE 0 "Not Available" 1 "Available" 3 "Active";
VAL_ 903 ACC_ACTIVE 0 "INACTIVE";
VAL_ 903 ACC_AVAILABLE 0 "NOT AVAILABLE" 1 "AVAILABLE" 2 "ON STOP" 3 "TEMP UNAVAILABLE";
VAL_ 903 AEB_ACTIVE 0 "AEB ON" 2 "AEB OFF" 3 "AEB TRIGGERED";
VAL_ 914 SIGN_SIGNAL 1 "RIGHT" 2 "LEFT";
VAL_ 914 DOOR_LOCK 0 "DOOR LOCKED" 1 "DOOR UNLOCKED";
VAL_ 930 ACC_STATE 1 "NOT AVAILABLE" 2 "AVAILABLE" 3 "ACTIVE";
VAL_ 1270 EPB_SIGNAL 2 "RELEASE" 3 "LOCK" 0 "ACTIVE_RELEASE" 1 "ACTIVE_LOCK";
VAL_ 1272 NEW_SIGNAL_1 3 "Open Driver Window" 4 "Close Driver Window";
VAL_ 1335 DRIVE_MODE 0 "Eco Mode" 1 "Normal Mode" 2 "Sport Mode";
